# PY32F040xx register map
Vendor: Puya; Series: PY32F0; File version: 1.0.0
CPU: CM0+ r0p1, little endian, no MPU, no FPU, 4 interrupt priority bits
Registers are 32-bit, read-write, reset 0x0 unless marked. A register's access mark holds for its fields unless they carry their own. Offsets are from the block's base; [hi:lo] are bit positions; {n}, {i} and the like mark numbered series; 'fields as' and 'values as' point back to an identical list.

## RCC — Reset and clock control
Base 0x40021000
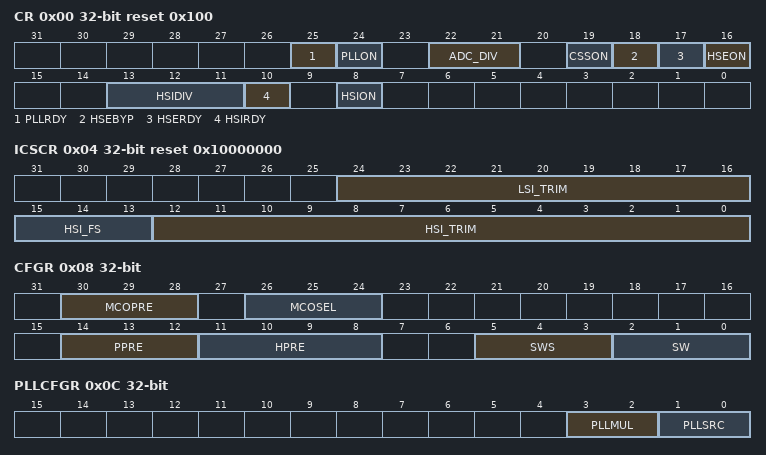
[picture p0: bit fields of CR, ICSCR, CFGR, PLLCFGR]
0x00 CR reset 0x100 — Clock control register
  [25] PLLRDY — PLL clock ready flag
    on read: 0=Unlocked (PLL unlocked); 1=Locked (PLL locked)
  [24] PLLON — PLL enable
    0=Off (Clock disabled); 1=On (Clock enabled)
  [22:21] ADC_DIV — ADC Frequency Division
  [19] CSSON — Clock security system enable
    0=Off (Clock disabled); 1=On (Clock enabled)
  [18] HSEBYP — HSE crystal oscillator bypass
    0=NotBypassed (HSE oscillator not bypassed); 1=Bypassed (HSE oscillator bypassed)
  [17] HSERDY — HSE clock ready flag
    on read: 0=NotReady (Oscillator is not stable); 1=Ready (Oscillator is stable)
  [16] HSEON — HSE clock enable
    0=Off (Clock disabled); 1=On (Clock enabled)
  [13:11] HSIDIV — HSI16 clock division factor
    0=NotDivided (no HSI division requested); 1=Div2 (HSI division by 2 requested); 2=Div4 (HSI division by 4 requested); 3=Div8 (HSI division by 8 requested); 4=Div16 (HSI division by 16 requested); 5=Div32 (HSI division by 32 requested); 6=Div64 (HSI division by 64 requested); 7=Div128 (HSI division by 128 requested)
  [10] HSIRDY — HSI16 clock ready flag
    values as HSERDY
  [8] HSION — HSI16 clock enable
    0=Off (Clock disabled); 1=On (Clock enabled)
0x04 ICSCR reset 0x10000000 — Internal clock sources calibration register
  [24:16] LSI_TRIM range 0..255 — LSI clock trimming
  [15:13] HSI_FS — HSI frequency selection
    0=Freq4MHz (Select internal 4 MHz oscilator); 1=Freq8MHz (Select internal 8 MHz oscilator); 2=Freq16MHz (Select internal 16 MHz oscilator); 3=Freq22_12MHz (Select internal 22.12 MHz oscilator); 4=Freq24MHz (Select internal 24 MHz oscilator)
  [12:0] HSI_TRIM range 0..31 — HSI clock trimming
0x08 CFGR — Clock configuration register
  [30:28] MCOPRE — Microcontroller clock output prescaler
    0=NotDivided (No division); 1=Div2 (Division by 2); 2=Div4 (Division by 4); 3=Div8 (Division by 8); 4=Div16 (Division by 16); 5=Div32 (Division by 32); 6=Div64 (Division by 64); 7=Div128 (Division by 128)
  [26:24] MCOSEL — Microcontroller clock output
    0=NoClock; 1=SYSCLK (SYSCLK clock selected); 3=HSI (MSI oscillator clock selected); 4=HSE (HSE oscillator clock selected); 5=PLL (PLL clock selected); 6=LSI (LSI oscillator clock selected); 7=LSE (LSE oscillator clock selected)
  [14:12] PPRE — APB prescaler
    3=NotDivided (HCLK not divided); 4=Div2 (HCLK divided by 2); 5=Div4 (HCLK divided by 4); 6=Div8 (HCLK divided by 8); 7=Div16 (HCLK divided by 16)
  [11:8] HPRE — AHB prescaler
    7=NotDivided (system clock not divided); 8=Div2 (system clock divided by 2); 9=Div4 (system clock divided by 4); 10=Div8 (system clock divided by 8); 11=Div16 (system clock divided by 16); 12=Div64 (system clock divided by 64); 13=Div128 (system clock divided by 128); 14=Div256 (system clock divided by 256); 15=Div512 (system clock divided by 512)
  [5:3] SWS ro — System clock switch status
    0=HSISYS (HSI oscillator used as system clock); 1=HSE (HSE oscillator used as system clock); 2=PLL (PLL used as system clock); 3=LSI (LSI oscillator used as system clock); 4=LSE (LSE oscillator used as system clock)
  [2:0] SW — System clock switch
    values as SWS
0x0C PLLCFGR — PLL configuration register
  [3:2] PLLMUL
  [1:0] PLLSRC — PLL clock source selection
    0=HSI (HSI selected as PLL input clock); 1=HSE (HSE selected as PLL input clock)
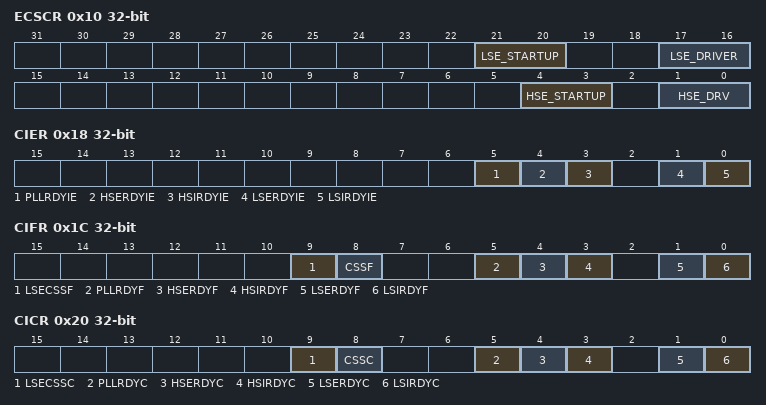
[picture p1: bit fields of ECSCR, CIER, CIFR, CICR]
0x10 ECSCR — External clock source control register
  [21:20] LSE_STARTUP
    0=ClockCycles1 (LSEBYP=0 4096 LSE clock cycles, LSEBYP=1 2048 LSE clock cycles); 1=ClockCycles2 (LSEBYP=0 2048 LSE clock cycles, LSEBYP=1 1024 LSE clock cycles); 2=ClockCycles3 (LSEBYP=0 8192 LSE clock cycles, LSEBYP=1 4096 LSE clock cycles); 3=Direct Output, regardless of stabilization time
  [17:16] LSE_DRIVER — LSE clock driver selection
    0=Disabled (Disable LSE drive); 1=Low (Lowest drive); 2=Medium drive; 3=Highest drive
  [4:3] HSE_STARTUP
    0=ClockCycles1 (HSEBYP=0 4096 LSE clock cycles, HSEBYP=1 2048 LSE clock cycles); 1=ClockCycles2 (HSEBYP=0 2048 LSE clock cycles, HSEBYP=1 1024 LSE clock cycles); 2=ClockCycles3 (HSEBYP=0 8192 LSE clock cycles, HSEBYP=1 4096 LSE clock cycles); 3=Direct Output, regardless of stabilization time
  [1:0] HSE_DRV
    0=Disabled (Disable HSE drive); 1=Low (Lowest drive); 2=Medium drive; 3=Highest drive
0x18 CIER — Clock interrupt enable register
  [all] fields
    0=Disabled (Ready interrupt disabled); 1=Enabled (Ready interrupt enabled)
  [5] PLLRDYIE — PLL ready interrupt enable
  [4] HSERDYIE — HSE ready interrupt enable
  [3] HSIRDYIE — HSI ready interrupt enable
  [1] LSERDYIE — LSE ready interrupt enable
  [0] LSIRDYIE — LSI ready interrupt enable
0x1C CIFR ro — Clock interrupt flag register
  [9] LSECSSF — LSE clock secure system interrupt flag
    0=No failure detected on LSE clock failure; 1=Failure detected on LSE clock failure
  [8] CSSF — HSE clock secure system interrupt flag
    0=No clock security interrupt caused by HSE clock failure; 1=Clock security interrupt caused by HSE clock failure
  [5] PLLRDYF — PLL ready interrupt flag
    0=NotInterrupted (No clock ready interrupt); 1=Interrupted (Clock ready interrupt)
  [4] HSERDYF — HSE ready interrupt flag
    values as PLLRDYF
  [3] HSIRDYF — HSI ready interrupt flag
    values as PLLRDYF
  [1] LSERDYF — LSE ready interrupt flag
    values as PLLRDYF
  [0] LSIRDYF — LSI ready interrupt flag
    values as PLLRDYF
0x20 CICR wo — Clock interrupt clear register
  [9] LSECSSC — LSE clock secure system interrupt flag clear
    1=Clear LSE clock secure system interrupt flag
  [8] CSSC — clock secure system interrupt flag clear
  [5] PLLRDYC — PLL ready interrupt clear
    1=Clear interrupt flag
  [4] HSERDYC — HSE ready interrupt clear
    1=Clear interrupt flag
  [3] HSIRDYC — HSI ready interrupt clear
    1=Clear interrupt flag
  [1] LSERDYC — LSE ready interrupt clear
    1=Clear interrupt flag
  [0] LSIRDYC — LSI ready interrupt clear
    1=Clear interrupt flag
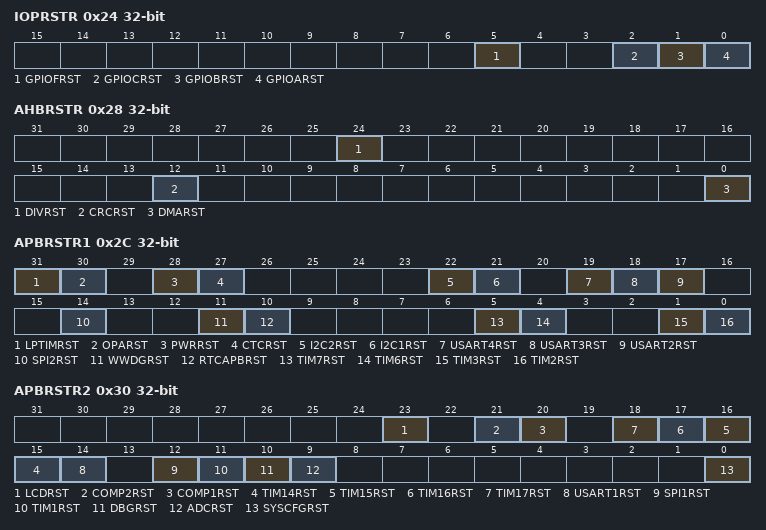
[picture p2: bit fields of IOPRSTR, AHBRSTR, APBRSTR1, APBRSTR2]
0x24 IOPRSTR — GPIO reset register
  [all] fields
    1=Reset I/O port
  [5] GPIOFRST — I/O port F reset
  [2] GPIOCRST — I/O port F reset
  [1] GPIOBRST — I/O port B reset
  [0] GPIOARST — I/O port A reset
0x28 AHBRSTR — AHB peripheral reset register
  [all] fields
    on write: 1=Reset the module
  [24] DIVRST — DIV reset
  [12] CRCRST — CRC reset
  [0] DMARST — DMA reset
0x2C APBRSTR1 — APB peripheral reset register 1
  [all] fields
    on write: 1=Reset the module
  [31] LPTIMRST — Low Power Timer reset
  [30] OPARST
  [28] PWRRST — Power interface reset
  [27] CTCRST
  [22] I2C2RST — I2C2 reset
  [21] I2C1RST — I2C1 reset
  [19] USART4RST — USART4 reset
  [18] USART3RST — USART3 reset
  [17] USART2RST — USART2 reset
  [14] SPI2RST — SPI2 reset
  [11] WWDGRST — WWDG reset
  [10] RTCAPBRST — RTCAPB reset
  [5] TIM7RST — TIM7 timer reset
  [4] TIM6RST — TIM6 timer reset
  [1] TIM3RST — TIM3 timer reset
  [0] TIM2RST — TIM2 timer reset
0x30 APBRSTR2 — APB peripheral reset register 2
  [all] fields
    on write: 1=Reset the module
  [23] LCDRST — LCD reset
  [21] COMP2RST — COMP2 reset
  [20] COMP1RST — COMP1 reset
  [n+1] TIM{n}RST (n=14..17) — TIM{n} reset
  [14] USART1RST — USART1 reset
  [12] SPI1RST — SPI1 reset
  [11] TIM1RST — TIM1 reset
  [10] DBGRST — DBG reset
  [9] ADCRST — ADC reset
  [0] SYSCFGRST — SYSCFG reset
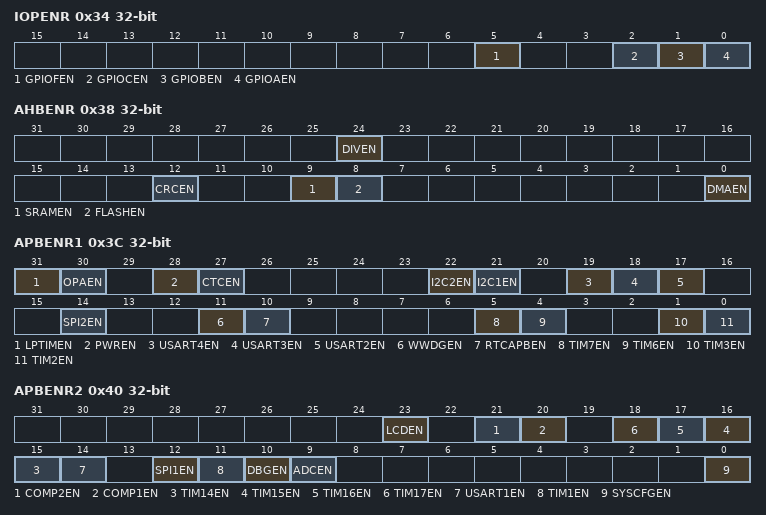
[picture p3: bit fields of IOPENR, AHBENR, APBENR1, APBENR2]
0x34 IOPENR — GPIO clock enable register
  [all] fields
    0=Disabled (Port clock disabled); 1=Enabled (Port clock enabled)
  [5] GPIOFEN — I/O port F clock enable
  [2] GPIOCEN — I/O port C clock enable
  [1] GPIOBEN — I/O port B clock enable
  [0] GPIOAEN — I/O port A clock enable
0x38 AHBENR — AHB peripheral clock enable register
  [all] fields
    0=Disabled (Clock disabled); 1=Enabled (Clock enabled)
  [24] DIVEN
  [12] CRCEN — CRC clock enable
  [9] SRAMEN — SRAM memory interface clock enable
  [8] FLASHEN — Flash memory interface clock enable
  [0] DMAEN — DMA clock enable
0x3C APBENR1 — APB peripheral clock enable register 1
  [all] fields
    0=Disabled (Clock disabled); 1=Enabled (Clock enabled)
  [31] LPTIMEN — LPTIM clock enable
  [30] OPAEN — OPA clock enable
  [28] PWREN — Power interface clock enable
  [27] CTCEN — CTC clock enable
  [22] I2C2EN — I2C2 clock enable
  [21] I2C1EN — I2C1 clock enable
  [19] USART4EN — USART4 clock enable
  [18] USART3EN — USART3 clock enable
  [17] USART2EN — USART2 clock enable
  [14] SPI2EN — SPI2 clock enable
  [11] WWDGEN — WWDG clock enable
  [10] RTCAPBEN — RTC APB clock enable
  [5] TIM7EN — TIM7 timer clock enable
  [4] TIM6EN — TIM6 timer clock enable
  [1] TIM3EN — TIM3 timer clock enable
  [0] TIM2EN — TIM2 timer clock enable
0x40 APBENR2 — APB peripheral clock enable register 2
  [all] fields
    0=Disabled (Clock disabled); 1=Enabled (Clock enabled)
  [23] LCDEN — LCD clock enable
  [21] COMP2EN — COMP2 clock enable
  [20] COMP1EN — COMP1 clock enable
  [n+1] TIM{n}EN (n=14..17) — TIM{n} clock enable
  [14] USART1EN — USART1 clock enable
  [12] SPI1EN — SPI1 clock enable
  [11] TIM1EN — TIM1 clock enable
  [10] DBGEN — DBG clock enable
  [9] ADCEN — ADCEN clock enable
  [0] SYSCFGEN — SYSCFG, COMP and VREFBUF clock enable
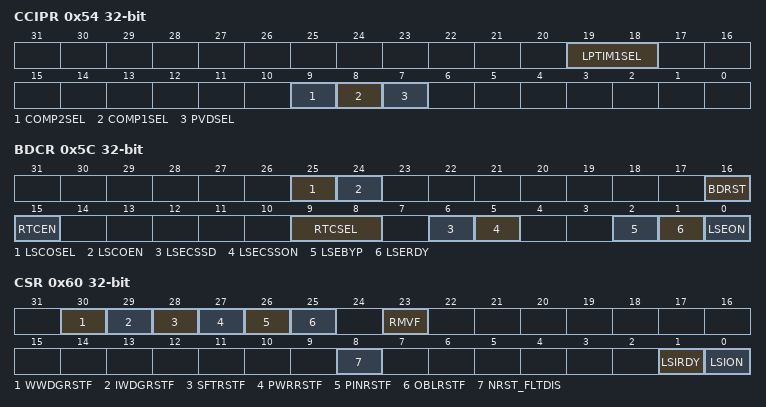
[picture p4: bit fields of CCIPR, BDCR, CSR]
0x54 CCIPR — Peripherals independent clock configuration register
  [19:18] LPTIM1SEL — LPTIM1 clock source selection
    0=PCLK (APB clock selected as Timer clock); 1=LSI (LSI clock selected as Timer clock); 3=LSE (LSE clock selected as Timer clock)
  [9] COMP2SEL — COMP2 clock source selection
    0=PCLK (APB clock selected as Timer clock); 1=LSC (LSC clock (LSI or LSE selected by LSCOSEL) selected as Timer clock)
  [8] COMP1SEL — COMP1 clock source selection
    values as COMP2SEL
  [7] PVDSEL — PVD detect clock source selection
0x5C BDCR — RTC domain control register
  [25] LSCOSEL — Low-speed clock output selection
    0=LSI (LSI clock selected); 1=LSE (LSE clock selected)
  [24] LSCOEN — Low-speed clock output (LSCO) enable
    0=Disabled (LSCO disabled); 1=Enabled (LSCO enabled)
  [16] BDRST — RTC domain software reset
    0=Disabled (Reset not activated); 1=Enabled (Reset the entire RTC domain)
  [15] RTCEN — RTC clock source enable
    0=Disabled (RTC clock disabled); 1=Enabled (RTC clock enabled)
  [9:8] RTCSEL — RTC clock source selection
    0=NoClock; 1=LSE (LSE oscillator clock used as RTC clock); 2=LSI (LSI oscillator clock used as RTC clock); 3=HSE (HSE oscillator clock divided by a prescaler used as RTC clock)
  [6] LSECSSD — LSE CSS detect
    on read: 0=No failure detected on LSE (32 kHz oscillator); 1=Failure detected on LSE (32 kHz oscillator)
  [5] LSECSSON — LSE CSS enable
    0=Off (CSS on LSE (32 kHz external oscillator) OFF); 1=On (CSS on LSE (32 kHz external oscillator) ON)
  [2] LSEBYP — LSE oscillator bypass
    0=NotBypassed (LSE crystal oscillator not bypassed); 1=Bypassed (LSE crystal oscillator bypassed with external clock)
  [1] LSERDY — LSE oscillator ready
    on read: 0=NotReady (LSE oscillator not ready); 1=Ready (LSE oscillator ready)
  [0] LSEON — LSE oscillator enable
    0=Off (LSE oscillator Off); 1=On (LSE oscillator On)
0x60 CSR — Control/status register
  [30] WWDGRSTF — Window watchdog reset flag
    on read: 0=No reset has occured; 1=Reset (A reset has occured)
  [29] IWDGRSTF — Independent window watchdog reset flag
    values as WWDGRSTF
  [28] SFTRSTF — Software reset flag
    values as WWDGRSTF
  [27] PWRRSTF — BOR or POR/PDR flag
    values as WWDGRSTF
  [26] PINRSTF — Pin reset flag
    values as WWDGRSTF
  [25] OBLRSTF — Option byte loader reset flag
    values as WWDGRSTF
  [23] RMVF — Remove reset flags
    on write: 1=Clears the reset flag
  [8] NRST_FLTDIS — NRST_FLTDIS oscillator ready
  [1] LSIRDY — LSI oscillator ready
    0=NotReady (Oscillator not ready); 1=Ready (Oscillator ready)
  [0] LSION — LSI oscillator enable
    0=Off (Oscillator OFF); 1=On (Oscillator ON)
